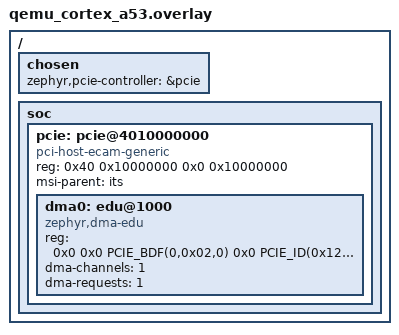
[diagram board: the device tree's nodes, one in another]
/*
 * Copyright (c) 2021 BayLibre, SAS
 *
 * SPDX-License-Identifier: Apache-2.0
 *
 */

#include <dt-bindings/pcie/pcie.h>

/ {
	chosen {
		zephyr,pcie-controller = &pcie;
	};

	soc {
		pcie: pcie@4010000000 {
			compatible = "pci-host-ecam-generic";
			#address-cells = <3>;
			#size-cells = <2>;
			reg = <0x40 0x10000000 0x0 0x10000000>;
			ranges = <0x1000000 0 0 0 0x3eff0000 0 0x10000>,
				 <0x2000000 0 0x10000000 0 0x10000000 0 0x2eff0000>,
				 <0x3000000 0x80 0 0x80 0 0x80 0>;
			msi-parent = <&its>;
			status = "okay";

			dma0: edu@1000 {
				#dma-cells = <1>;
				compatible = "zephyr,dma-edu";
				reg = <0x0 0x0 PCIE_BDF(0,0x02,0) 0x0 PCIE_ID(0x1234,0x11e8)>;
				dma-channels = <1>;
				dma-requests = <1>;
				status = "okay";
			};
        };
	};
};
